AUTOSAR XML (schema 4-2-2)
package /STELLANTIS/EPT/ASWCs
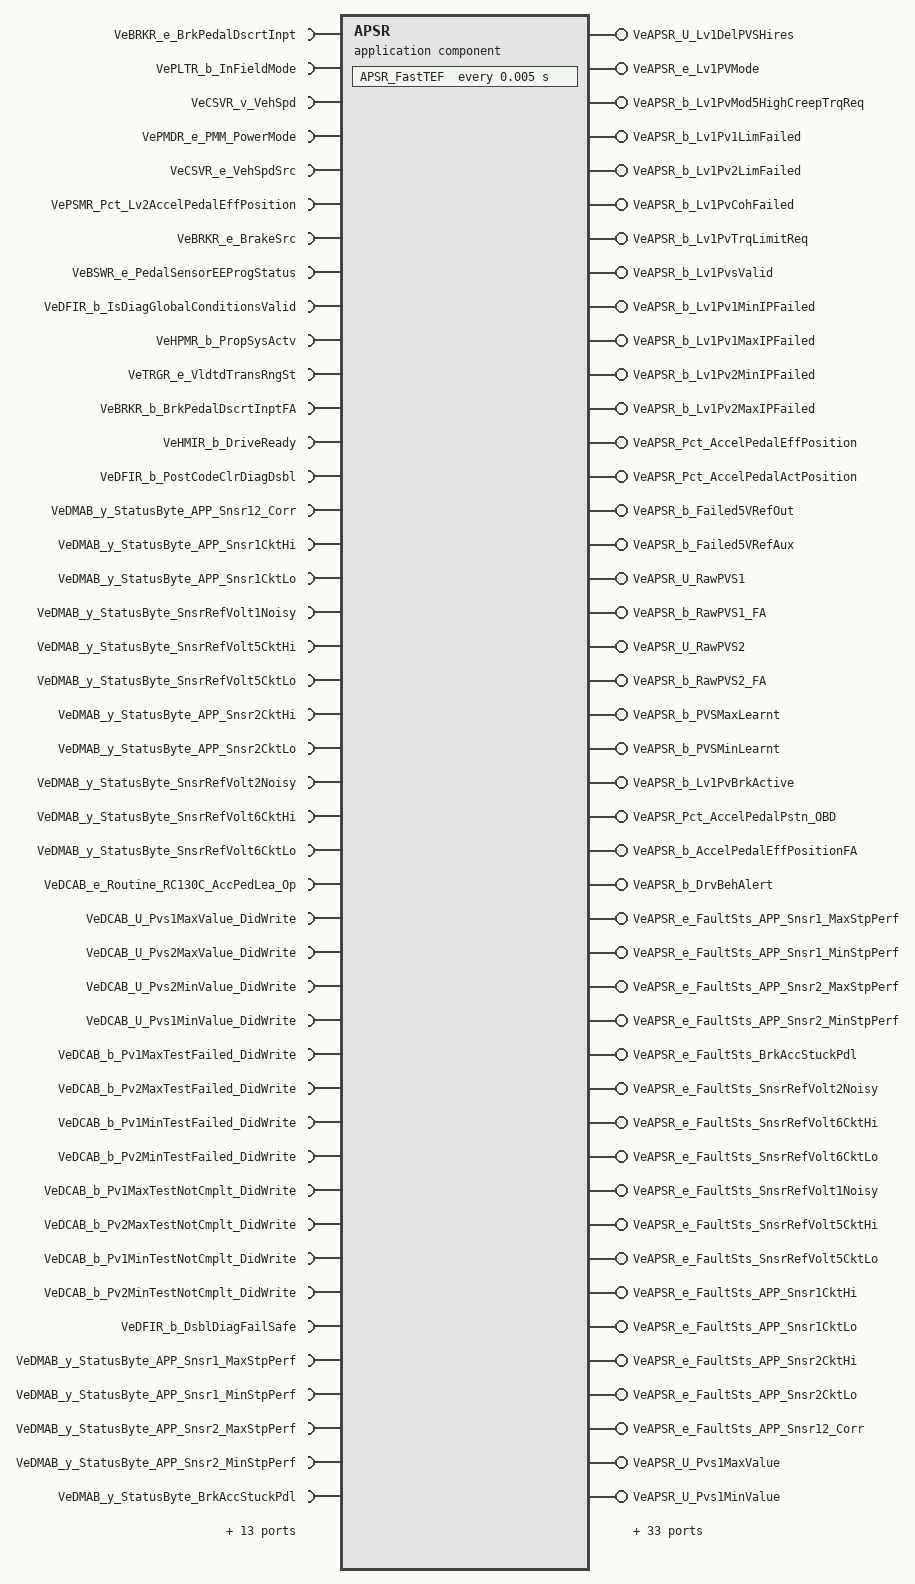
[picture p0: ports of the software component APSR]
  application sw component type APSR
    44 x require port:
      VeBRKR_e_BrkPedalDscrtInpt: variation-point={short-label=vpVeBRKR_e_BrkPedalDscrtInpt, sw-syscond=1}, nonqueued-receiver-com-spec{data-element=Value, init-value=CeBRKR_e_BrkNotApplied}, required-interface=VeBRKR_e_BrkPedalDscrtInpt
      VePLTR_b_InFieldMode: variation-point={short-label=vpVePLTR_b_InFieldMode, sw-syscond=1}, nonqueued-receiver-com-spec{data-element=Value, init-value=0}, required-interface=VePLTR_b_InFieldMode
      VeCSVR_v_VehSpd: variation-point={short-label=vpVeCSVR_v_VehSpd, sw-syscond=1}, nonqueued-receiver-com-spec{data-element=Value, init-value=0}, required-interface=VeCSVR_v_VehSpd
      VePMDR_e_PMM_PowerMode: variation-point={short-label=vpVePMDR_e_PMM_PowerMode, sw-syscond=1}, nonqueued-receiver-com-spec{data-element=Value, init-value=CePMDR_e_PowerMode_Off}, required-interface=VePMDR_e_PMM_PowerMode
      VeCSVR_e_VehSpdSrc: variation-point={short-label=vpVeCSVR_e_VehSpdSrc, sw-syscond=1}, nonqueued-receiver-com-spec{data-element=Value, init-value=CeCSVR_e_VehSpdFrmCAN}, required-interface=VeCSVR_e_VehSpdSrc
      VePSMR_Pct_Lv2AccelPedalEffPosition: variation-point={short-label=vpVePSMR_Pct_Lv2AccelPedalEffPosition, sw-syscond=1}, nonqueued-receiver-com-spec{data-element=Value, init-value=0}, required-interface=VePSMR_Pct_Lv2AccelPedalEffPosition
      VeBRKR_e_BrakeSrc: variation-point={short-label=vpVeBRKR_e_BrakeSrc, sw-syscond=1}, nonqueued-receiver-com-spec{data-element=Value, init-value=CeBRKR_e_BrkPdlDscrtInpt}, required-interface=VeBRKR_e_BrakeSrc
      VeBSWR_e_PedalSensorEEProgStatus: variation-point={short-label=vpVeBSWR_e_PedalSensorEEProgStatus, sw-syscond=1}, nonqueued-receiver-com-spec{data-element=Value, init-value=0}, required-interface=VeBSWR_e_PedalSensorEEProgStatus
      VeDFIR_b_IsDiagGlobalConditionsValid: variation-point={short-label=vpVeDFIR_b_IsDiagGlobalConditionsValid, sw-syscond=1}, nonqueued-receiver-com-spec{data-element=Value, init-value=0}, required-interface=VeDFIR_b_IsDiagGlobalConditionsValid
      VeHPMR_b_PropSysActv: variation-point={short-label=vpVeHPMR_b_PropSysActv, sw-syscond=1}, nonqueued-receiver-com-spec{data-element=Value, init-value=0}, required-interface=VeHPMR_b_PropSysActv
      VeTRGR_e_VldtdTransRngSt: variation-point={short-label=vpVeTRGR_e_VldtdTransRngSt, sw-syscond=1}, nonqueued-receiver-com-spec{data-element=Value, init-value=CeTRGR_e_NoSelectionAvailable}, required-interface=VeTRGR_e_VldtdTransRngSt
      VeBRKR_b_BrkPedalDscrtInptFA: variation-point={short-label=vpVeBRKR_b_BrkPedalDscrtInptFA, sw-syscond=1}, nonqueued-receiver-com-spec{data-element=Value, init-value=0}, required-interface=VeBRKR_b_BrkPedalDscrtInptFA
      VeHMIR_b_DriveReady: variation-point={short-label=vpVeHMIR_b_DriveReady, sw-syscond=1}, nonqueued-receiver-com-spec{data-element=Value, init-value=0}, required-interface=VeHMIR_b_DriveReady
      VeDFIR_b_PostCodeClrDiagDsbl: variation-point={short-label=vpVeDFIR_b_PostCodeClrDiagDsbl, sw-syscond=1}, nonqueued-receiver-com-spec{data-element=Value, init-value=0}, required-interface=VeDFIR_b_PostCodeClrDiagDsbl
      VeDMAB_y_StatusByte_APP_Snsr12_Corr: variation-point={short-label=vpVeDMAB_y_StatusByte_APP_Snsr12_Corr, sw-syscond=1}, nonqueued-receiver-com-spec{data-element=Value, init-value=0}, required-interface=VeDMAB_y_StatusByte_APP_Snsr12_Corr
      VeDMAB_y_StatusByte_APP_Snsr1CktHi: variation-point={short-label=vpVeDMAB_y_StatusByte_APP_Snsr1CktHi, sw-syscond=1}, nonqueued-receiver-com-spec{data-element=Value, init-value=0}, required-interface=VeDMAB_y_StatusByte_APP_Snsr1CktHi
      VeDMAB_y_StatusByte_APP_Snsr1CktLo: variation-point={short-label=vpVeDMAB_y_StatusByte_APP_Snsr1CktLo, sw-syscond=1}, nonqueued-receiver-com-spec{data-element=Value, init-value=0}, required-interface=VeDMAB_y_StatusByte_APP_Snsr1CktLo
      VeDMAB_y_StatusByte_SnsrRefVolt1Noisy: variation-point={short-label=vpVeDMAB_y_StatusByte_SnsrRefVolt1Noisy, sw-syscond=1}, nonqueued-receiver-com-spec{data-element=Value, init-value=0}, required-interface=VeDMAB_y_StatusByte_SnsrRefVolt1Noisy
      VeDMAB_y_StatusByte_SnsrRefVolt5CktHi: variation-point={short-label=vpVeDMAB_y_StatusByte_SnsrRefVolt5CktHi, sw-syscond=1}, nonqueued-receiver-com-spec{data-element=Value, init-value=0}, required-interface=VeDMAB_y_StatusByte_SnsrRefVolt5CktHi
      VeDMAB_y_StatusByte_SnsrRefVolt5CktLo: variation-point={short-label=vpVeDMAB_y_StatusByte_SnsrRefVolt5CktLo, sw-syscond=1}, nonqueued-receiver-com-spec{data-element=Value, init-value=0}, required-interface=VeDMAB_y_StatusByte_SnsrRefVolt5CktLo
      VeDMAB_y_StatusByte_APP_Snsr2CktHi: variation-point={short-label=vpVeDMAB_y_StatusByte_APP_Snsr2CktHi, sw-syscond=1}, nonqueued-receiver-com-spec{data-element=Value, init-value=0}, required-interface=VeDMAB_y_StatusByte_APP_Snsr2CktHi
      VeDMAB_y_StatusByte_APP_Snsr2CktLo: variation-point={short-label=vpVeDMAB_y_StatusByte_APP_Snsr2CktLo, sw-syscond=1}, nonqueued-receiver-com-spec{data-element=Value, init-value=0}, required-interface=VeDMAB_y_StatusByte_APP_Snsr2CktLo
      VeDMAB_y_StatusByte_SnsrRefVolt2Noisy: variation-point={short-label=vpVeDMAB_y_StatusByte_SnsrRefVolt2Noisy, sw-syscond=1}, nonqueued-receiver-com-spec{data-element=Value, init-value=0}, required-interface=VeDMAB_y_StatusByte_SnsrRefVolt2Noisy
      VeDMAB_y_StatusByte_SnsrRefVolt6CktHi: variation-point={short-label=vpVeDMAB_y_StatusByte_SnsrRefVolt6CktHi, sw-syscond=1}, nonqueued-receiver-com-spec{data-element=Value, init-value=0}, required-interface=VeDMAB_y_StatusByte_SnsrRefVolt6CktHi
      VeDMAB_y_StatusByte_SnsrRefVolt6CktLo: variation-point={short-label=vpVeDMAB_y_StatusByte_SnsrRefVolt6CktLo, sw-syscond=1}, nonqueued-receiver-com-spec{data-element=Value, init-value=0}, required-interface=VeDMAB_y_StatusByte_SnsrRefVolt6CktLo
      VeDCAB_e_Routine_RC130C_AccPedLea_Op: variation-point={short-label=vpVeDCAB_e_Routine_RC130C_AccPedLea_Op, sw-syscond=1}, nonqueued-receiver-com-spec{data-element=Value, init-value=CeDCAB_e_Routine_NOP}, required-interface=VeDCAB_e_Routine_RC130C_AccPedLea_Op
      VeDCAB_U_Pvs1MaxValue_DidWrite: nonqueued-receiver-com-spec{data-element=Value, init-value=0}, required-interface=VeDCAB_U_Pvs1MaxValue_DidWrite
      VeDCAB_U_Pvs2MaxValue_DidWrite: nonqueued-receiver-com-spec{data-element=Value, init-value=0}, required-interface=VeDCAB_U_Pvs2MaxValue_DidWrite
      VeDCAB_U_Pvs2MinValue_DidWrite: nonqueued-receiver-com-spec{data-element=Value, init-value=0}, required-interface=VeDCAB_U_Pvs2MinValue_DidWrite
      VeDCAB_U_Pvs1MinValue_DidWrite: nonqueued-receiver-com-spec{data-element=Value, init-value=0}, required-interface=VeDCAB_U_Pvs1MinValue_DidWrite
      VeDCAB_b_Pv1MaxTestFailed_DidWrite: nonqueued-receiver-com-spec{data-element=Value, init-value=0}, required-interface=VeDCAB_b_Pv1MaxTestFailed_DidWrite
      VeDCAB_b_Pv2MaxTestFailed_DidWrite: nonqueued-receiver-com-spec{data-element=Value, init-value=0}, required-interface=VeDCAB_b_Pv2MaxTestFailed_DidWrite
      VeDCAB_b_Pv1MinTestFailed_DidWrite: nonqueued-receiver-com-spec{data-element=Value, init-value=0}, required-interface=VeDCAB_b_Pv1MinTestFailed_DidWrite
      VeDCAB_b_Pv2MinTestFailed_DidWrite: nonqueued-receiver-com-spec{data-element=Value, init-value=0}, required-interface=VeDCAB_b_Pv2MinTestFailed_DidWrite
      VeDCAB_b_Pv1MaxTestNotCmplt_DidWrite: nonqueued-receiver-com-spec{data-element=Value, init-value=0}, required-interface=VeDCAB_b_Pv1MaxTestNotCmplt_DidWrite
      VeDCAB_b_Pv2MaxTestNotCmplt_DidWrite: nonqueued-receiver-com-spec{data-element=Value, init-value=0}, required-interface=VeDCAB_b_Pv2MaxTestNotCmplt_DidWrite
      VeDCAB_b_Pv1MinTestNotCmplt_DidWrite: nonqueued-receiver-com-spec{data-element=Value, init-value=0}, required-interface=VeDCAB_b_Pv1MinTestNotCmplt_DidWrite
      VeDCAB_b_Pv2MinTestNotCmplt_DidWrite: nonqueued-receiver-com-spec{data-element=Value, init-value=0}, required-interface=VeDCAB_b_Pv2MinTestNotCmplt_DidWrite
      VeDFIR_b_DsblDiagFailSafe: variation-point={short-label=vpVeDFIR_b_DsblDiagFailSafe, sw-syscond=1}, nonqueued-receiver-com-spec{data-element=Value, init-value=0}, required-interface=VeDFIR_b_DsblDiagFailSafe
      VeDMAB_y_StatusByte_APP_Snsr1_MaxStpPerf: variation-point={short-label=vpVeDMAB_y_StatusByte_APP_Snsr1_MaxStpPerf, sw-syscond=1}, nonqueued-receiver-com-spec{data-element=Value, init-value=0}, required-interface=VeDMAB_y_StatusByte_APP_Snsr1_MaxStpPerf
      VeDMAB_y_StatusByte_APP_Snsr1_MinStpPerf: variation-point={short-label=vpVeDMAB_y_StatusByte_APP_Snsr1_MinStpPerf, sw-syscond=1}, nonqueued-receiver-com-spec{data-element=Value, init-value=0}, required-interface=VeDMAB_y_StatusByte_APP_Snsr1_MinStpPerf
      VeDMAB_y_StatusByte_APP_Snsr2_MaxStpPerf: variation-point={short-label=vpVeDMAB_y_StatusByte_APP_Snsr2_MaxStpPerf, sw-syscond=1}, nonqueued-receiver-com-spec{data-element=Value, init-value=0}, required-interface=VeDMAB_y_StatusByte_APP_Snsr2_MaxStpPerf
      VeDMAB_y_StatusByte_APP_Snsr2_MinStpPerf: variation-point={short-label=vpVeDMAB_y_StatusByte_APP_Snsr2_MinStpPerf, sw-syscond=1}, nonqueued-receiver-com-spec{data-element=Value, init-value=0}, required-interface=VeDMAB_y_StatusByte_APP_Snsr2_MinStpPerf
      VeDMAB_y_StatusByte_BrkAccStuckPdl: variation-point={short-label=vpVeDMAB_y_StatusByte_BrkAccStuckPdl, sw-syscond=1}, nonqueued-receiver-com-spec{data-element=Value, init-value=0}, required-interface=VeDMAB_y_StatusByte_BrkAccStuckPdl
    64 x provide port:
      VeAPSR_U_Lv1DelPVSHires: nonqueued-sender-com-spec{data-element=Value, init-value=0}, provided-interface=VeAPSR_U_Lv1DelPVSHires
      VeAPSR_e_Lv1PVMode: nonqueued-sender-com-spec{data-element=Value, init-value=CeAPSR_e_LV1PVMode_NotValid}, provided-interface=VeAPSR_e_Lv1PVMode
      VeAPSR_b_Lv1PvMod5HighCreepTrqReq: nonqueued-sender-com-spec{data-element=Value, init-value=0}, provided-interface=VeAPSR_b_Lv1PvMod5HighCreepTrqReq
      VeAPSR_b_Lv1Pv1LimFailed: nonqueued-sender-com-spec{data-element=Value, init-value=0}, provided-interface=VeAPSR_b_Lv1Pv1LimFailed
      VeAPSR_b_Lv1Pv2LimFailed: nonqueued-sender-com-spec{data-element=Value, init-value=0}, provided-interface=VeAPSR_b_Lv1Pv2LimFailed
      VeAPSR_b_Lv1PvCohFailed: nonqueued-sender-com-spec{data-element=Value, init-value=0}, provided-interface=VeAPSR_b_Lv1PvCohFailed
      VeAPSR_b_Lv1PvTrqLimitReq: nonqueued-sender-com-spec{data-element=Value, init-value=0}, provided-interface=VeAPSR_b_Lv1PvTrqLimitReq
      VeAPSR_b_Lv1PvsValid: nonqueued-sender-com-spec{data-element=Value, init-value=0}, provided-interface=VeAPSR_b_Lv1PvsValid
      VeAPSR_b_Lv1Pv1MinIPFailed: nonqueued-sender-com-spec{data-element=Value, init-value=0}, provided-interface=VeAPSR_b_Lv1Pv1MinIPFailed
      VeAPSR_b_Lv1Pv1MaxIPFailed: nonqueued-sender-com-spec{data-element=Value, init-value=0}, provided-interface=VeAPSR_b_Lv1Pv1MaxIPFailed
      VeAPSR_b_Lv1Pv2MinIPFailed: nonqueued-sender-com-spec{data-element=Value, init-value=0}, provided-interface=VeAPSR_b_Lv1Pv2MinIPFailed
      VeAPSR_b_Lv1Pv2MaxIPFailed: nonqueued-sender-com-spec{data-element=Value, init-value=0}, provided-interface=VeAPSR_b_Lv1Pv2MaxIPFailed
      VeAPSR_Pct_AccelPedalEffPosition: variation-point={short-label=vpVeAPSR_Pct_AccelPedalEffPosition, sw-syscond=1}, nonqueued-sender-com-spec{data-element=Value, init-value=0}, provided-interface=VeAPSR_Pct_AccelPedalEffPosition
      VeAPSR_Pct_AccelPedalActPosition: variation-point={short-label=vpVeAPSR_Pct_AccelPedalActPosition, sw-syscond=1}, nonqueued-sender-com-spec{data-element=Value, init-value=0}, provided-interface=VeAPSR_Pct_AccelPedalActPosition
      VeAPSR_b_Failed5VRefOut: nonqueued-sender-com-spec{data-element=Value, init-value=0}, provided-interface=VeAPSR_b_Failed5VRefOut
      VeAPSR_b_Failed5VRefAux: nonqueued-sender-com-spec{data-element=Value, init-value=0}, provided-interface=VeAPSR_b_Failed5VRefAux
      VeAPSR_U_RawPVS1: variation-point={short-label=vpVeAPSR_U_RawPVS1, sw-syscond=1}, nonqueued-sender-com-spec{data-element=Value, init-value=0}, provided-interface=VeAPSR_U_RawPVS1
      VeAPSR_b_RawPVS1_FA: variation-point={short-label=vpVeAPSR_b_RawPVS1_FA, sw-syscond=1}, nonqueued-sender-com-spec{data-element=Value, init-value=0}, provided-interface=VeAPSR_b_RawPVS1_FA
      VeAPSR_U_RawPVS2: variation-point={short-label=vpVeAPSR_U_RawPVS2, sw-syscond=1}, nonqueued-sender-com-spec{data-element=Value, init-value=0}, provided-interface=VeAPSR_U_RawPVS2
      VeAPSR_b_RawPVS2_FA: variation-point={short-label=vpVeAPSR_b_RawPVS2_FA, sw-syscond=1}, nonqueued-sender-com-spec{data-element=Value, init-value=0}, provided-interface=VeAPSR_b_RawPVS2_FA
      VeAPSR_b_PVSMaxLearnt: nonqueued-sender-com-spec{data-element=Value, init-value=0}, provided-interface=VeAPSR_b_PVSMaxLearnt
      VeAPSR_b_PVSMinLearnt: nonqueued-sender-com-spec{data-element=Value, init-value=0}, provided-interface=VeAPSR_b_PVSMinLearnt
      VeAPSR_b_Lv1PvBrkActive: nonqueued-sender-com-spec{data-element=Value, init-value=0}, provided-interface=VeAPSR_b_Lv1PvBrkActive
      VeAPSR_Pct_AccelPedalPstn_OBD: nonqueued-sender-com-spec{data-element=Value, init-value=0}, provided-interface=VeAPSR_Pct_AccelPedalPstn_OBD
      VeAPSR_b_AccelPedalEffPositionFA: nonqueued-sender-com-spec{data-element=Value, init-value=0}, provided-interface=VeAPSR_b_AccelPedalEffPositionFA
      VeAPSR_b_DrvBehAlert: nonqueued-sender-com-spec{data-element=Value, init-value=0}, provided-interface=VeAPSR_b_DrvBehAlert
      VeAPSR_e_FaultSts_APP_Snsr1_MaxStpPerf: nonqueued-sender-com-spec{data-element=Value, init-value=CeDFIB_e_Init}, provided-interface=VeAPSR_e_FaultSts_APP_Snsr1_MaxStpPerf
      VeAPSR_e_FaultSts_APP_Snsr1_MinStpPerf: nonqueued-sender-com-spec{data-element=Value, init-value=CeDFIB_e_Init}, provided-interface=VeAPSR_e_FaultSts_APP_Snsr1_MinStpPerf
      VeAPSR_e_FaultSts_APP_Snsr2_MaxStpPerf: nonqueued-sender-com-spec{data-element=Value, init-value=CeDFIB_e_Init}, provided-interface=VeAPSR_e_FaultSts_APP_Snsr2_MaxStpPerf
      VeAPSR_e_FaultSts_APP_Snsr2_MinStpPerf: nonqueued-sender-com-spec{data-element=Value, init-value=CeDFIB_e_Init}, provided-interface=VeAPSR_e_FaultSts_APP_Snsr2_MinStpPerf
      VeAPSR_e_FaultSts_BrkAccStuckPdl: nonqueued-sender-com-spec{data-element=Value, init-value=CeDFIB_e_Init}, provided-interface=VeAPSR_e_FaultSts_BrkAccStuckPdl
      VeAPSR_e_FaultSts_SnsrRefVolt2Noisy: nonqueued-sender-com-spec{data-element=Value, init-value=CeDFIB_e_Init}, provided-interface=VeAPSR_e_FaultSts_SnsrRefVolt2Noisy
      VeAPSR_e_FaultSts_SnsrRefVolt6CktHi: nonqueued-sender-com-spec{data-element=Value, init-value=CeDFIB_e_Init}, provided-interface=VeAPSR_e_FaultSts_SnsrRefVolt6CktHi
      VeAPSR_e_FaultSts_SnsrRefVolt6CktLo: nonqueued-sender-com-spec{data-element=Value, init-value=CeDFIB_e_Init}, provided-interface=VeAPSR_e_FaultSts_SnsrRefVolt6CktLo
      VeAPSR_e_FaultSts_SnsrRefVolt1Noisy: nonqueued-sender-com-spec{data-element=Value, init-value=CeDFIB_e_Init}, provided-interface=VeAPSR_e_FaultSts_SnsrRefVolt1Noisy
      VeAPSR_e_FaultSts_SnsrRefVolt5CktHi: nonqueued-sender-com-spec{data-element=Value, init-value=CeDFIB_e_Init}, provided-interface=VeAPSR_e_FaultSts_SnsrRefVolt5CktHi
      VeAPSR_e_FaultSts_SnsrRefVolt5CktLo: nonqueued-sender-com-spec{data-element=Value, init-value=CeDFIB_e_Init}, provided-interface=VeAPSR_e_FaultSts_SnsrRefVolt5CktLo
      VeAPSR_e_FaultSts_APP_Snsr1CktHi: nonqueued-sender-com-spec{data-element=Value, init-value=CeDFIB_e_Init}, provided-interface=VeAPSR_e_FaultSts_APP_Snsr1CktHi
      VeAPSR_e_FaultSts_APP_Snsr1CktLo: nonqueued-sender-com-spec{data-element=Value, init-value=CeDFIB_e_Init}, provided-interface=VeAPSR_e_FaultSts_APP_Snsr1CktLo
      VeAPSR_e_FaultSts_APP_Snsr2CktHi: nonqueued-sender-com-spec{data-element=Value, init-value=CeDFIB_e_Init}, provided-interface=VeAPSR_e_FaultSts_APP_Snsr2CktHi
      VeAPSR_e_FaultSts_APP_Snsr2CktLo: nonqueued-sender-com-spec{data-element=Value, init-value=CeDFIB_e_Init}, provided-interface=VeAPSR_e_FaultSts_APP_Snsr2CktLo
      VeAPSR_e_FaultSts_APP_Snsr12_Corr: nonqueued-sender-com-spec{data-element=Value, init-value=CeDFIB_e_Init}, provided-interface=VeAPSR_e_FaultSts_APP_Snsr12_Corr
      VeAPSR_U_Pvs1MaxValue: nonqueued-sender-com-spec{data-element=Value, init-value=0}, provided-interface=VeAPSR_U_Pvs1MaxValue
      VeAPSR_U_Pvs1MinValue: nonqueued-sender-com-spec{data-element=Value, init-value=0}, provided-interface=VeAPSR_U_Pvs1MinValue
      VeAPSR_U_Pvs2MaxValue: nonqueued-sender-com-spec{data-element=Value, init-value=0}, provided-interface=VeAPSR_U_Pvs2MaxValue
      VeAPSR_U_Pvs2MinValue: nonqueued-sender-com-spec{data-element=Value, init-value=0}, provided-interface=VeAPSR_U_Pvs2MinValue
      VeAPSR_b_Pv1MaxTestFailed: nonqueued-sender-com-spec{data-element=Value, init-value=0}, provided-interface=VeAPSR_b_Pv1MaxTestFailed
      VeAPSR_b_Pv1MaxTestNotCmplt: nonqueued-sender-com-spec{data-element=Value, init-value=0}, provided-interface=VeAPSR_b_Pv1MaxTestNotCmplt
      VeAPSR_b_Pv1MinTestFailed: nonqueued-sender-com-spec{data-element=Value, init-value=0}, provided-interface=VeAPSR_b_Pv1MinTestFailed
      VeAPSR_b_Pv1MinTestNotCmplt: nonqueued-sender-com-spec{data-element=Value, init-value=0}, provided-interface=VeAPSR_b_Pv1MinTestNotCmplt
      VeAPSR_b_Pv2MaxTestFailed: nonqueued-sender-com-spec{data-element=Value, init-value=0}, provided-interface=VeAPSR_b_Pv2MaxTestFailed
      VeAPSR_b_Pv2MaxTestNotCmplt: nonqueued-sender-com-spec{data-element=Value, init-value=0}, provided-interface=VeAPSR_b_Pv2MaxTestNotCmplt
      VeAPSR_b_Pv2MinTestFailed: nonqueued-sender-com-spec{data-element=Value, init-value=0}, provided-interface=VeAPSR_b_Pv2MinTestFailed
      VeAPSR_b_Pv2MinTestNotCmplt: nonqueued-sender-com-spec{data-element=Value, init-value=0}, provided-interface=VeAPSR_b_Pv2MinTestNotCmplt
      VeAPSR_b_KickDown: nonqueued-sender-com-spec{data-element=Value, init-value=0}, provided-interface=VeAPSR_b_KickDown
      FsftAPSR_Pct_AccelPedalActPosition: server-com-spec=FsftAPSR_Pct_AccelPedalActPosition, provided-interface=FsftAPSR_Pct_AccelPedalActPosition
      FsftAPSR_Pct_AccelPedalEffPosition: server-com-spec=FsftAPSR_Pct_AccelPedalEffPosition, provided-interface=FsftAPSR_Pct_AccelPedalEffPosition
      PokeAPSR_Pct_AccelPedalActPosition: server-com-spec{operation=PokeAPSR_Pct_AccelPedalActPosition, queue-length=1}, provided-interface=PokeAPSR_Pct_AccelPedalActPosition
      PokeAPSR_Pct_AccelPedalEffPosition: server-com-spec{operation=PokeAPSR_Pct_AccelPedalEffPosition, queue-length=1}, provided-interface=PokeAPSR_Pct_AccelPedalEffPosition
      PokeAPSR_Pct_AccelPedalPstn_OBD: server-com-spec{operation=PokeAPSR_Pct_AccelPedalPstn_OBD, queue-length=1}, provided-interface=PokeAPSR_Pct_AccelPedalPstn_OBD
      PokeAPSR_U_RawAux5V: server-com-spec{operation=PokeAPSR_U_RawAux5V, queue-length=1}, provided-interface=PokeAPSR_U_RawAux5V
      PokeAPSR_U_RawOut5V: server-com-spec{operation=PokeAPSR_U_RawOut5V, queue-length=1}, provided-interface=PokeAPSR_U_RawOut5V
      PokeAPSR_U_RawPVS1: server-com-spec{operation=PokeAPSR_U_RawPVS1, queue-length=1}, provided-interface=PokeAPSR_U_RawPVS1
      PokeAPSR_U_RawPVS2: server-com-spec{operation=PokeAPSR_U_RawPVS2, queue-length=1}, provided-interface=PokeAPSR_U_RawPVS2
    13 x require port:
      NeAPSR_U_Lv1PvAdapt_Rx: nv-require-com-spec{init-value=0, variable=NeAPSR_U_Lv1PvAdapt}, required-interface=NeAPSR_U_Lv1PvAdapt
      AeAPSR_b_Pv1MaxTestFailed_Rx: nv-require-com-spec{init-value=0, variable=AeAPSR_b_Pv1MaxTestFailed}, required-interface=AeAPSR_b_Pv1MaxTestFailed
      AeAPSR_b_Pv1MaxTestNotCmplt_Rx: nv-require-com-spec{init-value=0, variable=AeAPSR_b_Pv1MaxTestNotCmplt}, required-interface=AeAPSR_b_Pv1MaxTestNotCmplt
      AeAPSR_b_Pv1MinTestFailed_Rx: nv-require-com-spec{init-value=0, variable=AeAPSR_b_Pv1MinTestFailed}, required-interface=AeAPSR_b_Pv1MinTestFailed
      AeAPSR_b_Pv1MinTestNotCmplt_Rx: nv-require-com-spec{init-value=0, variable=AeAPSR_b_Pv1MinTestNotCmplt}, required-interface=AeAPSR_b_Pv1MinTestNotCmplt
      AeAPSR_b_Pv2MaxTestFailed_Rx: nv-require-com-spec{init-value=0, variable=AeAPSR_b_Pv2MaxTestFailed}, required-interface=AeAPSR_b_Pv2MaxTestFailed
      AeAPSR_b_Pv2MaxTestNotCmplt_Rx: nv-require-com-spec{init-value=0, variable=AeAPSR_b_Pv2MaxTestNotCmplt}, required-interface=AeAPSR_b_Pv2MaxTestNotCmplt
      AeAPSR_b_Pv2MinTestFailed_Rx: nv-require-com-spec{init-value=0, variable=AeAPSR_b_Pv2MinTestFailed}, required-interface=AeAPSR_b_Pv2MinTestFailed
      AeAPSR_b_Pv2MinTestNotCmplt_Rx: nv-require-com-spec{init-value=0, variable=AeAPSR_b_Pv2MinTestNotCmplt}, required-interface=AeAPSR_b_Pv2MinTestNotCmplt
      AeAPSR_U_Pvs1MaxValue_Rx: nv-require-com-spec{init-value=0, variable=AeAPSR_U_Pvs1MaxValue}, required-interface=AeAPSR_U_Pvs1MaxValue
      AeAPSR_U_Pvs1MinValue_Rx: nv-require-com-spec{init-value=0, variable=AeAPSR_U_Pvs1MinValue}, required-interface=AeAPSR_U_Pvs1MinValue
      AeAPSR_U_Pvs2MaxValue_Rx: nv-require-com-spec{init-value=0, variable=AeAPSR_U_Pvs2MaxValue}, required-interface=AeAPSR_U_Pvs2MaxValue
      AeAPSR_U_Pvs2MinValue_Rx: nv-require-com-spec{init-value=0, variable=AeAPSR_U_Pvs2MinValue}, required-interface=AeAPSR_U_Pvs2MinValue
    13 x provide port:
      NeAPSR_U_Lv1PvAdapt: nv-provide-com-spec{ram-block-init-value=0, variable=NeAPSR_U_Lv1PvAdapt}, provided-interface=NeAPSR_U_Lv1PvAdapt
      AeAPSR_b_Pv1MaxTestFailed: variation-point={short-label=vpAeAPSR_b_Pv1MaxTestFailed, sw-syscond=1}, nv-provide-com-spec{ram-block-init-value=0, variable=AeAPSR_b_Pv1MaxTestFailed}, provided-interface=AeAPSR_b_Pv1MaxTestFailed
      AeAPSR_b_Pv1MaxTestNotCmplt: variation-point={short-label=vpAeAPSR_b_Pv1MaxTestNotCmplt, sw-syscond=1}, nv-provide-com-spec{ram-block-init-value=0, variable=AeAPSR_b_Pv1MaxTestNotCmplt}, provided-interface=AeAPSR_b_Pv1MaxTestNotCmplt
      AeAPSR_b_Pv1MinTestFailed: variation-point={short-label=vpAeAPSR_b_Pv1MinTestFailed, sw-syscond=1}, nv-provide-com-spec{ram-block-init-value=0, variable=AeAPSR_b_Pv1MinTestFailed}, provided-interface=AeAPSR_b_Pv1MinTestFailed
      AeAPSR_b_Pv1MinTestNotCmplt: variation-point={short-label=vpAeAPSR_b_Pv1MinTestNotCmplt, sw-syscond=1}, nv-provide-com-spec{ram-block-init-value=0, variable=AeAPSR_b_Pv1MinTestNotCmplt}, provided-interface=AeAPSR_b_Pv1MinTestNotCmplt
      AeAPSR_b_Pv2MaxTestFailed: variation-point={short-label=vpAeAPSR_b_Pv2MaxTestFailed, sw-syscond=1}, nv-provide-com-spec{ram-block-init-value=0, variable=AeAPSR_b_Pv2MaxTestFailed}, provided-interface=AeAPSR_b_Pv2MaxTestFailed
      AeAPSR_b_Pv2MaxTestNotCmplt: variation-point={short-label=vpAeAPSR_b_Pv2MaxTestNotCmplt, sw-syscond=1}, nv-provide-com-spec{ram-block-init-value=0, variable=AeAPSR_b_Pv2MaxTestNotCmplt}, provided-interface=AeAPSR_b_Pv2MaxTestNotCmplt
      AeAPSR_b_Pv2MinTestFailed: variation-point={short-label=vpAeAPSR_b_Pv2MinTestFailed, sw-syscond=1}, nv-provide-com-spec{ram-block-init-value=0, variable=AeAPSR_b_Pv2MinTestFailed}, provided-interface=AeAPSR_b_Pv2MinTestFailed
      AeAPSR_b_Pv2MinTestNotCmplt: variation-point={short-label=vpAeAPSR_b_Pv2MinTestNotCmplt, sw-syscond=1}, nv-provide-com-spec{ram-block-init-value=0, variable=AeAPSR_b_Pv2MinTestNotCmplt}, provided-interface=AeAPSR_b_Pv2MinTestNotCmplt
      AeAPSR_U_Pvs1MaxValue: variation-point={short-label=vpAeAPSR_U_Pvs1MaxValue, sw-syscond=1}, nv-provide-com-spec{ram-block-init-value=0, variable=AeAPSR_U_Pvs1MaxValue}, provided-interface=AeAPSR_U_Pvs1MaxValue
      AeAPSR_U_Pvs1MinValue: variation-point={short-label=vpAeAPSR_U_Pvs1MinValue, sw-syscond=1}, nv-provide-com-spec{ram-block-init-value=0, variable=AeAPSR_U_Pvs1MinValue}, provided-interface=AeAPSR_U_Pvs1MinValue
      AeAPSR_U_Pvs2MaxValue: variation-point={short-label=vpAeAPSR_U_Pvs2MaxValue, sw-syscond=1}, nv-provide-com-spec{ram-block-init-value=0, variable=AeAPSR_U_Pvs2MaxValue}, provided-interface=AeAPSR_U_Pvs2MaxValue
      AeAPSR_U_Pvs2MinValue: variation-point={short-label=vpAeAPSR_U_Pvs2MinValue, sw-syscond=1}, nv-provide-com-spec{ram-block-init-value=0, variable=AeAPSR_U_Pvs2MinValue}, provided-interface=AeAPSR_U_Pvs2MinValue
    behavior IB_APSR: data-type-mapping=msADTtoIDTMapping, handle-termination-and-restart=NO-SUPPORT
      timing event Event_FastTEF: start-on-event=APSR_FastTEF, period=0.005
      4 x operation invoked event:
        Event_PokeAPSR_U_RawAux5V: start-on-event=PokeAPSR_U_RawAux5V, operation=PokeAPSR_U_RawAux5V.PokeAPSR_U_RawAux5V
        Event_PokeAPSR_U_RawOut5V: start-on-event=PokeAPSR_U_RawOut5V, operation=PokeAPSR_U_RawOut5V.PokeAPSR_U_RawOut5V
        Event_PokeAPSR_U_RawPVS1: start-on-event=PokeAPSR_U_RawPVS1, operation=PokeAPSR_U_RawPVS1.PokeAPSR_U_RawPVS1
        Event_PokeAPSR_U_RawPVS2: start-on-event=PokeAPSR_U_RawPVS2, operation=PokeAPSR_U_RawPVS2.PokeAPSR_U_RawPVS2
      init event Event_APSR_ac_Init: start-on-event=APSR_ac_Init
      init event Event_PwrOn: start-on-event=APSR_PwrOn
      init event Event_PwrOff: start-on-event=APSR_PwrOff
      6 x data received event:
        Event_Routine_RC130C_AccPedLea: start-on-event=Routine_RC130C_AccPedLea, data=VeDCAB_e_Routine_RC130C_AccPedLea_Op.Value
        Event_DIDWrite_RWD9E21_IPEEETCPVS1MAXVAL: start-on-event=DIDWrite_RWD9E21_IPEEETCPVS1MAXVAL, data=VeDCAB_U_Pvs1MaxValue_DidWrite.Value
        Event_DIDWrite_RWD9E23_IPEEETCPVS2MAXVAL: start-on-event=DIDWrite_RWD9E23_IPEEETCPVS2MAXVAL, data=VeDCAB_U_Pvs2MaxValue_DidWrite.Value
        Event_DIDWrite_RWD9E22_IPEEETCPVS2MINVAL: start-on-event=DIDWrite_RWD9E22_IPEEETCPVS2MINVAL, data=VeDCAB_U_Pvs2MinValue_DidWrite.Value
        Event_DIDWrite_RWD9E20_IPEEETCPVS1MINVAL: start-on-event=DIDWrite_RWD9E20_IPEEETCPVS1MINVAL, data=VeDCAB_U_Pvs1MinValue_DidWrite.Value
        Event_DIDWrite_RWD9E15_IPEEREG16FLG: start-on-event=DIDWrite_RWD9E15_IPEEREG16FLG, data=VeDCAB_b_Pv1MaxTestFailed_DidWrite.Value
      explicit-inter-runnable-variables:
        8 x data, all with category=VALUE, sw-calibration-access=READ-ONLY, init-value=0:
          ServRoutStrt_write_IRV: type=Boolean, variation-point={short-label=vpServRoutStrt_write_IRV, sw-syscond=1}
          RawOut5V_FA_Init_write_IRV: type=Boolean, variation-point={short-label=vpRawOut5V_FA_Init_write_IRV, sw-syscond=1}
          RawAux5V_FA_Init_write_IRV: type=Boolean, variation-point={short-label=vpRawAux5V_FA_Init_write_IRV, sw-syscond=1}
          RawPVS1_write_IRV: type=Float, variation-point={short-label=vpRawPVS1_write_IRV, sw-syscond=1}
          RawPVS2_write_IRV: type=Float, variation-point={short-label=vpRawPVS2_write_IRV, sw-syscond=1}
          RawOut5V_Init_write_IRV: type=Float, variation-point={short-label=vpRawOut5V_Init_write_IRV, sw-syscond=1}
          RawAux5V_Init_write_IRV: type=Float, variation-point={short-label=vpRawAux5V_Init_write_IRV, sw-syscond=1}
          LeAPSR_b_AccelPedalEffPositionFA_write_IRV: type=Boolean
      14 x runnable:
        APSR_ac_Init
          data-send-points:
            17 x access:
              OUT_VeAPSR_e_Lv1PVMode_Value: accessed-variable=VeAPSR_e_Lv1PVMode.Value
              OUT_VeAPSR_e_FaultSts_APP_Snsr1_MaxStpPerf_Value: accessed-variable=VeAPSR_e_FaultSts_APP_Snsr1_MaxStpPerf.Value
              OUT_VeAPSR_e_FaultSts_APP_Snsr1_MinStpPerf_Value: accessed-variable=VeAPSR_e_FaultSts_APP_Snsr1_MinStpPerf.Value
              OUT_VeAPSR_e_FaultSts_APP_Snsr2_MaxStpPerf_Value: accessed-variable=VeAPSR_e_FaultSts_APP_Snsr2_MaxStpPerf.Value
              OUT_VeAPSR_e_FaultSts_APP_Snsr2_MinStpPerf_Value: accessed-variable=VeAPSR_e_FaultSts_APP_Snsr2_MinStpPerf.Value
              OUT_VeAPSR_e_FaultSts_BrkAccStuckPdl_Value: accessed-variable=VeAPSR_e_FaultSts_BrkAccStuckPdl.Value
              OUT_VeAPSR_e_FaultSts_SnsrRefVolt2Noisy_Value: accessed-variable=VeAPSR_e_FaultSts_SnsrRefVolt2Noisy.Value
              OUT_VeAPSR_e_FaultSts_SnsrRefVolt6CktHi_Value: accessed-variable=VeAPSR_e_FaultSts_SnsrRefVolt6CktHi.Value
              OUT_VeAPSR_e_FaultSts_SnsrRefVolt6CktLo_Value: accessed-variable=VeAPSR_e_FaultSts_SnsrRefVolt6CktLo.Value
              OUT_VeAPSR_e_FaultSts_SnsrRefVolt1Noisy_Value: accessed-variable=VeAPSR_e_FaultSts_SnsrRefVolt1Noisy.Value
              OUT_VeAPSR_e_FaultSts_SnsrRefVolt5CktHi_Value: accessed-variable=VeAPSR_e_FaultSts_SnsrRefVolt5CktHi.Value
              OUT_VeAPSR_e_FaultSts_SnsrRefVolt5CktLo_Value: accessed-variable=VeAPSR_e_FaultSts_SnsrRefVolt5CktLo.Value
              OUT_VeAPSR_e_FaultSts_APP_Snsr1CktHi_Value: accessed-variable=VeAPSR_e_FaultSts_APP_Snsr1CktHi.Value
              OUT_VeAPSR_e_FaultSts_APP_Snsr1CktLo_Value: accessed-variable=VeAPSR_e_FaultSts_APP_Snsr1CktLo.Value
              OUT_VeAPSR_e_FaultSts_APP_Snsr2CktHi_Value: accessed-variable=VeAPSR_e_FaultSts_APP_Snsr2CktHi.Value
              OUT_VeAPSR_e_FaultSts_APP_Snsr2CktLo_Value: accessed-variable=VeAPSR_e_FaultSts_APP_Snsr2CktLo.Value
              OUT_VeAPSR_e_FaultSts_APP_Snsr12_Corr_Value: accessed-variable=VeAPSR_e_FaultSts_APP_Snsr12_Corr.Value
        APSR_PwrOn
          data-receive-point-by-arguments:
            13 x access:
              IN_AeAPSR_U_Pvs1MaxValue_Rx_AeAPSR_U_Pvs1MaxValue: accessed-variable=AeAPSR_U_Pvs1MaxValue_Rx.AeAPSR_U_Pvs1MaxValue
              IN_AeAPSR_U_Pvs1MinValue_Rx_AeAPSR_U_Pvs1MinValue: accessed-variable=AeAPSR_U_Pvs1MinValue_Rx.AeAPSR_U_Pvs1MinValue
              IN_AeAPSR_U_Pvs2MaxValue_Rx_AeAPSR_U_Pvs2MaxValue: accessed-variable=AeAPSR_U_Pvs2MaxValue_Rx.AeAPSR_U_Pvs2MaxValue
              IN_AeAPSR_U_Pvs2MinValue_Rx_AeAPSR_U_Pvs2MinValue: accessed-variable=AeAPSR_U_Pvs2MinValue_Rx.AeAPSR_U_Pvs2MinValue
              IN_AeAPSR_b_Pv1MaxTestFailed_Rx_AeAPSR_b_Pv1MaxTestFailed: accessed-variable=AeAPSR_b_Pv1MaxTestFailed_Rx.AeAPSR_b_Pv1MaxTestFailed
              IN_AeAPSR_b_Pv1MaxTestNotCmplt_Rx_AeAPSR_b_Pv1MaxTestNotCmplt: accessed-variable=AeAPSR_b_Pv1MaxTestNotCmplt_Rx.AeAPSR_b_Pv1MaxTestNotCmplt
              IN_AeAPSR_b_Pv1MinTestFailed_Rx_AeAPSR_b_Pv1MinTestFailed: accessed-variable=AeAPSR_b_Pv1MinTestFailed_Rx.AeAPSR_b_Pv1MinTestFailed
              IN_AeAPSR_b_Pv1MinTestNotCmplt_Rx_AeAPSR_b_Pv1MinTestNotCmplt: accessed-variable=AeAPSR_b_Pv1MinTestNotCmplt_Rx.AeAPSR_b_Pv1MinTestNotCmplt
              IN_AeAPSR_b_Pv2MaxTestFailed_Rx_AeAPSR_b_Pv2MaxTestFailed: accessed-variable=AeAPSR_b_Pv2MaxTestFailed_Rx.AeAPSR_b_Pv2MaxTestFailed
              IN_AeAPSR_b_Pv2MaxTestNotCmplt_Rx_AeAPSR_b_Pv2MaxTestNotCmplt: accessed-variable=AeAPSR_b_Pv2MaxTestNotCmplt_Rx.AeAPSR_b_Pv2MaxTestNotCmplt
              IN_AeAPSR_b_Pv2MinTestFailed_Rx_AeAPSR_b_Pv2MinTestFailed: accessed-variable=AeAPSR_b_Pv2MinTestFailed_Rx.AeAPSR_b_Pv2MinTestFailed
              IN_AeAPSR_b_Pv2MinTestNotCmplt_Rx_AeAPSR_b_Pv2MinTestNotCmplt: accessed-variable=AeAPSR_b_Pv2MinTestNotCmplt_Rx.AeAPSR_b_Pv2MinTestNotCmplt
              IN_NeAPSR_U_Lv1PvAdapt_Rx_NeAPSR_U_Lv1PvAdapt: accessed-variable=NeAPSR_U_Lv1PvAdapt_Rx.NeAPSR_U_Lv1PvAdapt
          data-send-points:
            55 x access:
              OUT_VeAPSR_b_RawPVS1_FA_Value: accessed-variable=VeAPSR_b_RawPVS1_FA.Value, variation-point={short-label=vpOUT_VeAPSR_b_RawPVS1_FA_Value, sw-syscond=1}
              OUT_VeAPSR_U_RawPVS1_Value: accessed-variable=VeAPSR_U_RawPVS1.Value, variation-point={short-label=vpOUT_VeAPSR_U_RawPVS1_Value, sw-syscond=1}
              OUT_VeAPSR_b_RawPVS2_FA_Value: accessed-variable=VeAPSR_b_RawPVS2_FA.Value, variation-point={short-label=vpOUT_VeAPSR_b_RawPVS2_FA_Value, sw-syscond=1}
              OUT_VeAPSR_U_RawPVS2_Value: accessed-variable=VeAPSR_U_RawPVS2.Value, variation-point={short-label=vpOUT_VeAPSR_U_RawPVS2_Value, sw-syscond=1}
              OUT_VeAPSR_Pct_AccelPedalEffPosition_Value: accessed-variable=VeAPSR_Pct_AccelPedalEffPosition.Value, variation-point={short-label=vpOUT_VeAPSR_Pct_AccelPedalEffPosition_Value, sw-syscond=1}
              OUT_VeAPSR_Pct_AccelPedalActPosition_Value: accessed-variable=VeAPSR_Pct_AccelPedalActPosition.Value, variation-point={short-label=vpOUT_VeAPSR_Pct_AccelPedalActPosition_Value, sw-syscond=1}
              OUT_VeAPSR_Pct_AccelPedalPstn_OBD_Value: accessed-variable=VeAPSR_Pct_AccelPedalPstn_OBD.Value
              OUT_VeAPSR_b_AccelPedalEffPositionFA_Value: accessed-variable=VeAPSR_b_AccelPedalEffPositionFA.Value
              OUT_VeAPSR_e_Lv1PVMode_Value: accessed-variable=VeAPSR_e_Lv1PVMode.Value
              OUT_VeAPSR_U_Lv1DelPVSHires_Value: accessed-variable=VeAPSR_U_Lv1DelPVSHires.Value
              OUT_VeAPSR_b_Lv1PvMod5HighCreepTrqReq_Value: accessed-variable=VeAPSR_b_Lv1PvMod5HighCreepTrqReq.Value
              OUT_VeAPSR_b_Lv1Pv1LimFailed_Value: accessed-variable=VeAPSR_b_Lv1Pv1LimFailed.Value
              OUT_VeAPSR_b_Lv1Pv2LimFailed_Value: accessed-variable=VeAPSR_b_Lv1Pv2LimFailed.Value
              OUT_VeAPSR_b_Lv1PvCohFailed_Value: accessed-variable=VeAPSR_b_Lv1PvCohFailed.Value
              OUT_VeAPSR_b_Lv1PvTrqLimitReq_Value: accessed-variable=VeAPSR_b_Lv1PvTrqLimitReq.Value
              OUT_VeAPSR_b_Lv1PvsValid_Value: accessed-variable=VeAPSR_b_Lv1PvsValid.Value
              OUT_VeAPSR_b_Lv1Pv1MinIPFailed_Value: accessed-variable=VeAPSR_b_Lv1Pv1MinIPFailed.Value
              OUT_VeAPSR_b_Lv1Pv1MaxIPFailed_Value: accessed-variable=VeAPSR_b_Lv1Pv1MaxIPFailed.Value
              OUT_VeAPSR_b_Lv1Pv2MinIPFailed_Value: accessed-variable=VeAPSR_b_Lv1Pv2MinIPFailed.Value
              OUT_VeAPSR_b_Lv1Pv2MaxIPFailed_Value: accessed-variable=VeAPSR_b_Lv1Pv2MaxIPFailed.Value
              OUT_VeAPSR_b_Failed5VRefOut_Value: accessed-variable=VeAPSR_b_Failed5VRefOut.Value
              OUT_VeAPSR_b_Failed5VRefAux_Value: accessed-variable=VeAPSR_b_Failed5VRefAux.Value
              OUT_VeAPSR_b_PVSMaxLearnt_Value: accessed-variable=VeAPSR_b_PVSMaxLearnt.Value
              OUT_VeAPSR_b_PVSMinLearnt_Value: accessed-variable=VeAPSR_b_PVSMinLearnt.Value
              OUT_VeAPSR_b_Lv1PvBrkActive_Value: accessed-variable=VeAPSR_b_Lv1PvBrkActive.Value
              OUT_VeAPSR_b_DrvBehAlert_Value: accessed-variable=VeAPSR_b_DrvBehAlert.Value
              OUT_VeAPSR_b_KickDown_Value: accessed-variable=VeAPSR_b_KickDown.Value
              OUT_VeAPSR_e_FaultSts_APP_Snsr1_MaxStpPerf_Value: accessed-variable=VeAPSR_e_FaultSts_APP_Snsr1_MaxStpPerf.Value
              OUT_VeAPSR_e_FaultSts_APP_Snsr1_MinStpPerf_Value: accessed-variable=VeAPSR_e_FaultSts_APP_Snsr1_MinStpPerf.Value
              OUT_VeAPSR_e_FaultSts_APP_Snsr2_MaxStpPerf_Value: accessed-variable=VeAPSR_e_FaultSts_APP_Snsr2_MaxStpPerf.Value
              OUT_VeAPSR_e_FaultSts_APP_Snsr2_MinStpPerf_Value: accessed-variable=VeAPSR_e_FaultSts_APP_Snsr2_MinStpPerf.Value
              OUT_VeAPSR_e_FaultSts_BrkAccStuckPdl_Value: accessed-variable=VeAPSR_e_FaultSts_BrkAccStuckPdl.Value
              OUT_VeAPSR_e_FaultSts_SnsrRefVolt2Noisy_Value: accessed-variable=VeAPSR_e_FaultSts_SnsrRefVolt2Noisy.Value
              OUT_VeAPSR_e_FaultSts_SnsrRefVolt6CktHi_Value: accessed-variable=VeAPSR_e_FaultSts_SnsrRefVolt6CktHi.Value
              OUT_VeAPSR_e_FaultSts_SnsrRefVolt6CktLo_Value: accessed-variable=VeAPSR_e_FaultSts_SnsrRefVolt6CktLo.Value
              OUT_VeAPSR_e_FaultSts_SnsrRefVolt1Noisy_Value: accessed-variable=VeAPSR_e_FaultSts_SnsrRefVolt1Noisy.Value
              OUT_VeAPSR_e_FaultSts_SnsrRefVolt5CktHi_Value: accessed-variable=VeAPSR_e_FaultSts_SnsrRefVolt5CktHi.Value
              OUT_VeAPSR_e_FaultSts_SnsrRefVolt5CktLo_Value: accessed-variable=VeAPSR_e_FaultSts_SnsrRefVolt5CktLo.Value
              OUT_VeAPSR_e_FaultSts_APP_Snsr1CktHi_Value: accessed-variable=VeAPSR_e_FaultSts_APP_Snsr1CktHi.Value
              OUT_VeAPSR_e_FaultSts_APP_Snsr1CktLo_Value: accessed-variable=VeAPSR_e_FaultSts_APP_Snsr1CktLo.Value
              OUT_VeAPSR_e_FaultSts_APP_Snsr2CktHi_Value: accessed-variable=VeAPSR_e_FaultSts_APP_Snsr2CktHi.Value
              OUT_VeAPSR_e_FaultSts_APP_Snsr2CktLo_Value: accessed-variable=VeAPSR_e_FaultSts_APP_Snsr2CktLo.Value
              OUT_VeAPSR_e_FaultSts_APP_Snsr12_Corr_Value: accessed-variable=VeAPSR_e_FaultSts_APP_Snsr12_Corr.Value
              OUT_VeAPSR_U_Pvs1MaxValue_Value: accessed-variable=VeAPSR_U_Pvs1MaxValue.Value
              OUT_VeAPSR_U_Pvs1MinValue_Value: accessed-variable=VeAPSR_U_Pvs1MinValue.Value
              OUT_VeAPSR_U_Pvs2MaxValue_Value: accessed-variable=VeAPSR_U_Pvs2MaxValue.Value
              OUT_VeAPSR_U_Pvs2MinValue_Value: accessed-variable=VeAPSR_U_Pvs2MinValue.Value
              OUT_VeAPSR_b_Pv1MaxTestFailed_Value: accessed-variable=VeAPSR_b_Pv1MaxTestFailed.Value
              OUT_VeAPSR_b_Pv1MaxTestNotCmplt_Value: accessed-variable=VeAPSR_b_Pv1MaxTestNotCmplt.Value
              OUT_VeAPSR_b_Pv1MinTestFailed_Value: accessed-variable=VeAPSR_b_Pv1MinTestFailed.Value
              OUT_VeAPSR_b_Pv1MinTestNotCmplt_Value: accessed-variable=VeAPSR_b_Pv1MinTestNotCmplt.Value
              OUT_VeAPSR_b_Pv2MaxTestFailed_Value: accessed-variable=VeAPSR_b_Pv2MaxTestFailed.Value
              OUT_VeAPSR_b_Pv2MaxTestNotCmplt_Value: accessed-variable=VeAPSR_b_Pv2MaxTestNotCmplt.Value
              OUT_VeAPSR_b_Pv2MinTestFailed_Value: accessed-variable=VeAPSR_b_Pv2MinTestFailed.Value
              OUT_VeAPSR_b_Pv2MinTestNotCmplt_Value: accessed-variable=VeAPSR_b_Pv2MinTestNotCmplt.Value
          written-local-variables:
            8 x access:
              WV_LeAPSR_b_AccelPedalEffPositionFA_write_IRV: accessed-variable=LeAPSR_b_AccelPedalEffPositionFA_write_IRV
              WV_RawAux5V_FA_Init_write_IRV: accessed-variable=RawAux5V_FA_Init_write_IRV, variation-point={short-label=vpWV_RawAux5V_FA_Init_write_IRV, sw-syscond=1}
              WV_RawAux5V_Init_write_IRV: accessed-variable=RawAux5V_Init_write_IRV, variation-point={short-label=vpWV_RawAux5V_Init_write_IRV, sw-syscond=1}
              WV_RawOut5V_FA_Init_write_IRV: accessed-variable=RawOut5V_FA_Init_write_IRV, variation-point={short-label=vpWV_RawOut5V_FA_Init_write_IRV, sw-syscond=1}
              WV_RawOut5V_Init_write_IRV: accessed-variable=RawOut5V_Init_write_IRV, variation-point={short-label=vpWV_RawOut5V_Init_write_IRV, sw-syscond=1}
              WV_RawPVS1_write_IRV: accessed-variable=RawPVS1_write_IRV, variation-point={short-label=vpWV_RawPVS1_write_IRV, sw-syscond=1}
              WV_RawPVS2_write_IRV: accessed-variable=RawPVS2_write_IRV, variation-point={short-label=vpWV_RawPVS2_write_IRV, sw-syscond=1}
              WV_ServRoutStrt_write_IRV: accessed-variable=ServRoutStrt_write_IRV, variation-point={short-label=vpWV_ServRoutStrt_write_IRV, sw-syscond=1}
        APSR_FastTEF: variation-point={short-label=vpAPSR_FastTEF, sw-syscond=1}
          data-receive-point-by-arguments:
            31 x access:
              IN_VeBRKR_b_BrkPedalDscrtInptFA_Value: accessed-variable=VeBRKR_b_BrkPedalDscrtInptFA.Value, variation-point={short-label=vpIN_VeBRKR_b_BrkPedalDscrtInptFA_Value, sw-syscond=1}
              IN_VeBRKR_e_BrakeSrc_Value: accessed-variable=VeBRKR_e_BrakeSrc.Value, variation-point={short-label=vpIN_VeBRKR_e_BrakeSrc_Value, sw-syscond=1}
              IN_VeBRKR_e_BrkPedalDscrtInpt_Value: accessed-variable=VeBRKR_e_BrkPedalDscrtInpt.Value, variation-point={short-label=vpIN_VeBRKR_e_BrkPedalDscrtInpt_Value, sw-syscond=1}
              IN_VeBSWR_e_PedalSensorEEProgStatus_Value: accessed-variable=VeBSWR_e_PedalSensorEEProgStatus.Value, variation-point={short-label=vpIN_VeBSWR_e_PedalSensorEEProgStatus_Value, sw-syscond=1}
              IN_VeCSVR_e_VehSpdSrc_Value: accessed-variable=VeCSVR_e_VehSpdSrc.Value, variation-point={short-label=vpIN_VeCSVR_e_VehSpdSrc_Value, sw-syscond=1}
              IN_VeCSVR_v_VehSpd_Value: accessed-variable=VeCSVR_v_VehSpd.Value, variation-point={short-label=vpIN_VeCSVR_v_VehSpd_Value, sw-syscond=1}
              IN_VeDFIR_b_DsblDiagFailSafe_Value: accessed-variable=VeDFIR_b_DsblDiagFailSafe.Value, variation-point={short-label=vpIN_VeDFIR_b_DsblDiagFailSafe_Value, sw-syscond=1}
              IN_VeDFIR_b_IsDiagGlobalConditionsValid_Value: accessed-variable=VeDFIR_b_IsDiagGlobalConditionsValid.Value, variation-point={short-label=vpIN_VeDFIR_b_IsDiagGlobalConditionsValid_Value, sw-syscond=1}
              IN_VeDFIR_b_PostCodeClrDiagDsbl_Value: accessed-variable=VeDFIR_b_PostCodeClrDiagDsbl.Value, variation-point={short-label=vpIN_VeDFIR_b_PostCodeClrDiagDsbl_Value, sw-syscond=1}
              IN_VeDMAB_y_StatusByte_APP_Snsr12_Corr_Value: accessed-variable=VeDMAB_y_StatusByte_APP_Snsr12_Corr.Value, variation-point={short-label=vpIN_VeDMAB_y_StatusByte_APP_Snsr12_Corr_Value, sw-syscond=1}
              IN_VeDMAB_y_StatusByte_APP_Snsr1CktHi_Value: accessed-variable=VeDMAB_y_StatusByte_APP_Snsr1CktHi.Value, variation-point={short-label=vpIN_VeDMAB_y_StatusByte_APP_Snsr1CktHi_Value, sw-syscond=1}
              IN_VeDMAB_y_StatusByte_APP_Snsr1CktLo_Value: accessed-variable=VeDMAB_y_StatusByte_APP_Snsr1CktLo.Value, variation-point={short-label=vpIN_VeDMAB_y_StatusByte_APP_Snsr1CktLo_Value, sw-syscond=1}
              IN_VeDMAB_y_StatusByte_APP_Snsr1_MaxStpPerf_Value: accessed-variable=VeDMAB_y_StatusByte_APP_Snsr1_MaxStpPerf.Value, variation-point={short-label=vpIN_VeDMAB_y_StatusByte_APP_Snsr1_MaxStpPerf_Value, sw-syscond=1}
              IN_VeDMAB_y_StatusByte_APP_Snsr1_MinStpPerf_Value: accessed-variable=VeDMAB_y_StatusByte_APP_Snsr1_MinStpPerf.Value, variation-point={short-label=vpIN_VeDMAB_y_StatusByte_APP_Snsr1_MinStpPerf_Value, sw-syscond=1}
              IN_VeDMAB_y_StatusByte_APP_Snsr2CktHi_Value: accessed-variable=VeDMAB_y_StatusByte_APP_Snsr2CktHi.Value, variation-point={short-label=vpIN_VeDMAB_y_StatusByte_APP_Snsr2CktHi_Value, sw-syscond=1}
              IN_VeDMAB_y_StatusByte_APP_Snsr2CktLo_Value: accessed-variable=VeDMAB_y_StatusByte_APP_Snsr2CktLo.Value, variation-point={short-label=vpIN_VeDMAB_y_StatusByte_APP_Snsr2CktLo_Value, sw-syscond=1}
              IN_VeDMAB_y_StatusByte_APP_Snsr2_MaxStpPerf_Value: accessed-variable=VeDMAB_y_StatusByte_APP_Snsr2_MaxStpPerf.Value, variation-point={short-label=vpIN_VeDMAB_y_StatusByte_APP_Snsr2_MaxStpPerf_Value, sw-syscond=1}
              IN_VeDMAB_y_StatusByte_APP_Snsr2_MinStpPerf_Value: accessed-variable=VeDMAB_y_StatusByte_APP_Snsr2_MinStpPerf.Value, variation-point={short-label=vpIN_VeDMAB_y_StatusByte_APP_Snsr2_MinStpPerf_Value, sw-syscond=1}
              IN_VeDMAB_y_StatusByte_BrkAccStuckPdl_Value: accessed-variable=VeDMAB_y_StatusByte_BrkAccStuckPdl.Value, variation-point={short-label=vpIN_VeDMAB_y_StatusByte_BrkAccStuckPdl_Value, sw-syscond=1}
              IN_VeDMAB_y_StatusByte_SnsrRefVolt1Noisy_Value: accessed-variable=VeDMAB_y_StatusByte_SnsrRefVolt1Noisy.Value, variation-point={short-label=vpIN_VeDMAB_y_StatusByte_SnsrRefVolt1Noisy_Value, sw-syscond=1}
              IN_VeDMAB_y_StatusByte_SnsrRefVolt2Noisy_Value: accessed-variable=VeDMAB_y_StatusByte_SnsrRefVolt2Noisy.Value, variation-point={short-label=vpIN_VeDMAB_y_StatusByte_SnsrRefVolt2Noisy_Value, sw-syscond=1}
              IN_VeDMAB_y_StatusByte_SnsrRefVolt5CktHi_Value: accessed-variable=VeDMAB_y_StatusByte_SnsrRefVolt5CktHi.Value, variation-point={short-label=vpIN_VeDMAB_y_StatusByte_SnsrRefVolt5CktHi_Value, sw-syscond=1}
              IN_VeDMAB_y_StatusByte_SnsrRefVolt5CktLo_Value: accessed-variable=VeDMAB_y_StatusByte_SnsrRefVolt5CktLo.Value, variation-point={short-label=vpIN_VeDMAB_y_StatusByte_SnsrRefVolt5CktLo_Value, sw-syscond=1}
              IN_VeDMAB_y_StatusByte_SnsrRefVolt6CktHi_Value: accessed-variable=VeDMAB_y_StatusByte_SnsrRefVolt6CktHi.Value, variation-point={short-label=vpIN_VeDMAB_y_StatusByte_SnsrRefVolt6CktHi_Value, sw-syscond=1}
              IN_VeDMAB_y_StatusByte_SnsrRefVolt6CktLo_Value: accessed-variable=VeDMAB_y_StatusByte_SnsrRefVolt6CktLo.Value, variation-point={short-label=vpIN_VeDMAB_y_StatusByte_SnsrRefVolt6CktLo_Value, sw-syscond=1}
              IN_VeHMIR_b_DriveReady_Value: accessed-variable=VeHMIR_b_DriveReady.Value, variation-point={short-label=vpIN_VeHMIR_b_DriveReady_Value, sw-syscond=1}
              IN_VeHPMR_b_PropSysActv_Value: accessed-variable=VeHPMR_b_PropSysActv.Value, variation-point={short-label=vpIN_VeHPMR_b_PropSysActv_Value, sw-syscond=1}
              IN_VePLTR_b_InFieldMode_Value: accessed-variable=VePLTR_b_InFieldMode.Value, variation-point={short-label=vpIN_VePLTR_b_InFieldMode_Value, sw-syscond=1}
              IN_VePMDR_e_PMM_PowerMode_Value: accessed-variable=VePMDR_e_PMM_PowerMode.Value, variation-point={short-label=vpIN_VePMDR_e_PMM_PowerMode_Value, sw-syscond=1}
              IN_VePSMR_Pct_Lv2AccelPedalEffPosition_Value: accessed-variable=VePSMR_Pct_Lv2AccelPedalEffPosition.Value, variation-point={short-label=vpIN_VePSMR_Pct_Lv2AccelPedalEffPosition_Value, sw-syscond=1}
              IN_VeTRGR_e_VldtdTransRngSt_Value: accessed-variable=VeTRGR_e_VldtdTransRngSt.Value, variation-point={short-label=vpIN_VeTRGR_e_VldtdTransRngSt_Value, sw-syscond=1}
          data-send-points:
            62 x access:
              OUT_VeAPSR_e_Lv1PVMode_Value: accessed-variable=VeAPSR_e_Lv1PVMode.Value
              OUT_VeAPSR_Pct_AccelPedalEffPosition_Value: accessed-variable=VeAPSR_Pct_AccelPedalEffPosition.Value, variation-point={short-label=vpOUT_VeAPSR_Pct_AccelPedalEffPosition_Value, sw-syscond=1}
              OUT_VeAPSR_Pct_AccelPedalActPosition_Value: accessed-variable=VeAPSR_Pct_AccelPedalActPosition.Value, variation-point={short-label=vpOUT_VeAPSR_Pct_AccelPedalActPosition_Value, sw-syscond=1}
              OUT_VeAPSR_U_Lv1DelPVSHires_Value: accessed-variable=VeAPSR_U_Lv1DelPVSHires.Value
              OUT_VeAPSR_b_Lv1PvMod5HighCreepTrqReq_Value: accessed-variable=VeAPSR_b_Lv1PvMod5HighCreepTrqReq.Value
              OUT_VeAPSR_b_Lv1Pv1LimFailed_Value: accessed-variable=VeAPSR_b_Lv1Pv1LimFailed.Value
              OUT_VeAPSR_b_Lv1Pv2LimFailed_Value: accessed-variable=VeAPSR_b_Lv1Pv2LimFailed.Value
              OUT_VeAPSR_b_Lv1PvCohFailed_Value: accessed-variable=VeAPSR_b_Lv1PvCohFailed.Value
              OUT_VeAPSR_b_Lv1PvTrqLimitReq_Value: accessed-variable=VeAPSR_b_Lv1PvTrqLimitReq.Value
              OUT_VeAPSR_b_Lv1PvsValid_Value: accessed-variable=VeAPSR_b_Lv1PvsValid.Value
              OUT_VeAPSR_b_Lv1Pv1MinIPFailed_Value: accessed-variable=VeAPSR_b_Lv1Pv1MinIPFailed.Value
              OUT_VeAPSR_b_Lv1Pv1MaxIPFailed_Value: accessed-variable=VeAPSR_b_Lv1Pv1MaxIPFailed.Value
              OUT_VeAPSR_b_Lv1Pv2MinIPFailed_Value: accessed-variable=VeAPSR_b_Lv1Pv2MinIPFailed.Value
              OUT_VeAPSR_b_Lv1Pv2MaxIPFailed_Value: accessed-variable=VeAPSR_b_Lv1Pv2MaxIPFailed.Value
              OUT_VeAPSR_b_Failed5VRefOut_Value: accessed-variable=VeAPSR_b_Failed5VRefOut.Value
              OUT_VeAPSR_b_Failed5VRefAux_Value: accessed-variable=VeAPSR_b_Failed5VRefAux.Value
              OUT_VeAPSR_b_PVSMaxLearnt_Value: accessed-variable=VeAPSR_b_PVSMaxLearnt.Value
              OUT_VeAPSR_b_PVSMinLearnt_Value: accessed-variable=VeAPSR_b_PVSMinLearnt.Value
              OUT_VeAPSR_b_Lv1PvBrkActive_Value: accessed-variable=VeAPSR_b_Lv1PvBrkActive.Value
              OUT_VeAPSR_b_DrvBehAlert_Value: accessed-variable=VeAPSR_b_DrvBehAlert.Value
              OUT_VeAPSR_b_AccelPedalEffPositionFA_Value: accessed-variable=VeAPSR_b_AccelPedalEffPositionFA.Value
              OUT_VeAPSR_b_KickDown_Value: accessed-variable=VeAPSR_b_KickDown.Value
              OUT_VeAPSR_e_FaultSts_APP_Snsr1_MaxStpPerf_Value: accessed-variable=VeAPSR_e_FaultSts_APP_Snsr1_MaxStpPerf.Value
              OUT_VeAPSR_e_FaultSts_APP_Snsr1_MinStpPerf_Value: accessed-variable=VeAPSR_e_FaultSts_APP_Snsr1_MinStpPerf.Value
              OUT_VeAPSR_e_FaultSts_APP_Snsr2_MaxStpPerf_Value: accessed-variable=VeAPSR_e_FaultSts_APP_Snsr2_MaxStpPerf.Value
              OUT_VeAPSR_e_FaultSts_APP_Snsr2_MinStpPerf_Value: accessed-variable=VeAPSR_e_FaultSts_APP_Snsr2_MinStpPerf.Value
              OUT_VeAPSR_e_FaultSts_BrkAccStuckPdl_Value: accessed-variable=VeAPSR_e_FaultSts_BrkAccStuckPdl.Value
              OUT_VeAPSR_e_FaultSts_SnsrRefVolt2Noisy_Value: accessed-variable=VeAPSR_e_FaultSts_SnsrRefVolt2Noisy.Value
              OUT_VeAPSR_e_FaultSts_SnsrRefVolt6CktHi_Value: accessed-variable=VeAPSR_e_FaultSts_SnsrRefVolt6CktHi.Value
              OUT_VeAPSR_e_FaultSts_SnsrRefVolt6CktLo_Value: accessed-variable=VeAPSR_e_FaultSts_SnsrRefVolt6CktLo.Value
              OUT_VeAPSR_e_FaultSts_SnsrRefVolt1Noisy_Value: accessed-variable=VeAPSR_e_FaultSts_SnsrRefVolt1Noisy.Value
              OUT_VeAPSR_e_FaultSts_SnsrRefVolt5CktHi_Value: accessed-variable=VeAPSR_e_FaultSts_SnsrRefVolt5CktHi.Value
              OUT_VeAPSR_e_FaultSts_SnsrRefVolt5CktLo_Value: accessed-variable=VeAPSR_e_FaultSts_SnsrRefVolt5CktLo.Value
              OUT_VeAPSR_e_FaultSts_APP_Snsr1CktHi_Value: accessed-variable=VeAPSR_e_FaultSts_APP_Snsr1CktHi.Value
              OUT_VeAPSR_e_FaultSts_APP_Snsr1CktLo_Value: accessed-variable=VeAPSR_e_FaultSts_APP_Snsr1CktLo.Value
              OUT_VeAPSR_e_FaultSts_APP_Snsr2CktHi_Value: accessed-variable=VeAPSR_e_FaultSts_APP_Snsr2CktHi.Value
              OUT_VeAPSR_e_FaultSts_APP_Snsr2CktLo_Value: accessed-variable=VeAPSR_e_FaultSts_APP_Snsr2CktLo.Value
              OUT_VeAPSR_e_FaultSts_APP_Snsr12_Corr_Value: accessed-variable=VeAPSR_e_FaultSts_APP_Snsr12_Corr.Value
              OUT_AeAPSR_b_Pv1MaxTestFailed_AeAPSR_b_Pv1MaxTestFailed: accessed-variable=AeAPSR_b_Pv1MaxTestFailed.AeAPSR_b_Pv1MaxTestFailed, variation-point={short-label=vpOUT_AeAPSR_b_Pv1MaxTestFailed_AeAPSR_b_Pv1MaxTestFailed, sw-syscond=1}
              OUT_AeAPSR_b_Pv1MaxTestNotCmplt_AeAPSR_b_Pv1MaxTestNotCmplt: accessed-variable=AeAPSR_b_Pv1MaxTestNotCmplt.AeAPSR_b_Pv1MaxTestNotCmplt, variation-point={short-label=vpOUT_AeAPSR_b_Pv1MaxTestNotCmplt_AeAPSR_b_Pv1MaxTestNotCmplt, sw-syscond=1}
              OUT_AeAPSR_b_Pv1MinTestFailed_AeAPSR_b_Pv1MinTestFailed: accessed-variable=AeAPSR_b_Pv1MinTestFailed.AeAPSR_b_Pv1MinTestFailed, variation-point={short-label=vpOUT_AeAPSR_b_Pv1MinTestFailed_AeAPSR_b_Pv1MinTestFailed, sw-syscond=1}
              OUT_AeAPSR_b_Pv1MinTestNotCmplt_AeAPSR_b_Pv1MinTestNotCmplt: accessed-variable=AeAPSR_b_Pv1MinTestNotCmplt.AeAPSR_b_Pv1MinTestNotCmplt, variation-point={short-label=vpOUT_AeAPSR_b_Pv1MinTestNotCmplt_AeAPSR_b_Pv1MinTestNotCmplt, sw-syscond=1}
              OUT_AeAPSR_b_Pv2MaxTestFailed_AeAPSR_b_Pv2MaxTestFailed: accessed-variable=AeAPSR_b_Pv2MaxTestFailed.AeAPSR_b_Pv2MaxTestFailed, variation-point={short-label=vpOUT_AeAPSR_b_Pv2MaxTestFailed_AeAPSR_b_Pv2MaxTestFailed, sw-syscond=1}
              OUT_AeAPSR_b_Pv2MaxTestNotCmplt_AeAPSR_b_Pv2MaxTestNotCmplt: accessed-variable=AeAPSR_b_Pv2MaxTestNotCmplt.AeAPSR_b_Pv2MaxTestNotCmplt, variation-point={short-label=vpOUT_AeAPSR_b_Pv2MaxTestNotCmplt_AeAPSR_b_Pv2MaxTestNotCmplt, sw-syscond=1}
              OUT_AeAPSR_b_Pv2MinTestFailed_AeAPSR_b_Pv2MinTestFailed: accessed-variable=AeAPSR_b_Pv2MinTestFailed.AeAPSR_b_Pv2MinTestFailed, variation-point={short-label=vpOUT_AeAPSR_b_Pv2MinTestFailed_AeAPSR_b_Pv2MinTestFailed, sw-syscond=1}
              OUT_AeAPSR_b_Pv2MinTestNotCmplt_AeAPSR_b_Pv2MinTestNotCmplt: accessed-variable=AeAPSR_b_Pv2MinTestNotCmplt.AeAPSR_b_Pv2MinTestNotCmplt, variation-point={short-label=vpOUT_AeAPSR_b_Pv2MinTestNotCmplt_AeAPSR_b_Pv2MinTestNotCmplt, sw-syscond=1}
              OUT_AeAPSR_U_Pvs1MaxValue_AeAPSR_U_Pvs1MaxValue: accessed-variable=AeAPSR_U_Pvs1MaxValue.AeAPSR_U_Pvs1MaxValue, variation-point={short-label=vpOUT_AeAPSR_U_Pvs1MaxValue_AeAPSR_U_Pvs1MaxValue, sw-syscond=1}
              OUT_AeAPSR_U_Pvs1MinValue_AeAPSR_U_Pvs1MinValue: accessed-variable=AeAPSR_U_Pvs1MinValue.AeAPSR_U_Pvs1MinValue, variation-point={short-label=vpOUT_AeAPSR_U_Pvs1MinValue_AeAPSR_U_Pvs1MinValue, sw-syscond=1}
              OUT_AeAPSR_U_Pvs2MaxValue_AeAPSR_U_Pvs2MaxValue: accessed-variable=AeAPSR_U_Pvs2MaxValue.AeAPSR_U_Pvs2MaxValue, variation-point={short-label=vpOUT_AeAPSR_U_Pvs2MaxValue_AeAPSR_U_Pvs2MaxValue, sw-syscond=1}
              OUT_AeAPSR_U_Pvs2MinValue_AeAPSR_U_Pvs2MinValue: accessed-variable=AeAPSR_U_Pvs2MinValue.AeAPSR_U_Pvs2MinValue, variation-point={short-label=vpOUT_AeAPSR_U_Pvs2MinValue_AeAPSR_U_Pvs2MinValue, sw-syscond=1}
              OUT_VeAPSR_U_Pvs1MaxValue_Value: accessed-variable=VeAPSR_U_Pvs1MaxValue.Value
              OUT_VeAPSR_U_Pvs1MinValue_Value: accessed-variable=VeAPSR_U_Pvs1MinValue.Value
              OUT_VeAPSR_U_Pvs2MaxValue_Value: accessed-variable=VeAPSR_U_Pvs2MaxValue.Value
              OUT_VeAPSR_U_Pvs2MinValue_Value: accessed-variable=VeAPSR_U_Pvs2MinValue.Value
              OUT_VeAPSR_b_Pv1MaxTestFailed_Value: accessed-variable=VeAPSR_b_Pv1MaxTestFailed.Value
              OUT_VeAPSR_b_Pv1MaxTestNotCmplt_Value: accessed-variable=VeAPSR_b_Pv1MaxTestNotCmplt.Value
              OUT_VeAPSR_b_Pv1MinTestFailed_Value: accessed-variable=VeAPSR_b_Pv1MinTestFailed.Value
              OUT_VeAPSR_b_Pv1MinTestNotCmplt_Value: accessed-variable=VeAPSR_b_Pv1MinTestNotCmplt.Value
              OUT_VeAPSR_b_Pv2MaxTestFailed_Value: accessed-variable=VeAPSR_b_Pv2MaxTestFailed.Value
              OUT_VeAPSR_b_Pv2MaxTestNotCmplt_Value: accessed-variable=VeAPSR_b_Pv2MaxTestNotCmplt.Value
              OUT_VeAPSR_b_Pv2MinTestFailed_Value: accessed-variable=VeAPSR_b_Pv2MinTestFailed.Value
              OUT_VeAPSR_b_Pv2MinTestNotCmplt_Value: accessed-variable=VeAPSR_b_Pv2MinTestNotCmplt.Value
          read-local-variables:
            5 x access:
              RV_RawAux5V_Init_write_IRV: accessed-variable=RawAux5V_Init_write_IRV, variation-point={short-label=vpRV_RawAux5V_Init_write_IRV, sw-syscond=1}
              RV_RawOut5V_Init_write_IRV: accessed-variable=RawOut5V_Init_write_IRV, variation-point={short-label=vpRV_RawOut5V_Init_write_IRV, sw-syscond=1}
              RV_RawPVS1_write_IRV: accessed-variable=RawPVS1_write_IRV, variation-point={short-label=vpRV_RawPVS1_write_IRV, sw-syscond=1}
              RV_RawPVS2_write_IRV: accessed-variable=RawPVS2_write_IRV, variation-point={short-label=vpRV_RawPVS2_write_IRV, sw-syscond=1}
              RV_ServRoutStrt_write_IRV: accessed-variable=ServRoutStrt_write_IRV, variation-point={short-label=vpRV_ServRoutStrt_write_IRV, sw-syscond=1}
        APSR_PwrOff
          data-send-points:
            access OUT_NeAPSR_U_Lv1PvAdapt_NeAPSR_U_Lv1PvAdapt: accessed-variable=NeAPSR_U_Lv1PvAdapt.NeAPSR_U_Lv1PvAdapt
        Routine_RC130C_AccPedLea: variation-point={short-label=vpRoutine_RC130C_AccPedLea, sw-syscond=1}
          data-receive-point-by-arguments:
            access IN_VeDCAB_e_Routine_RC130C_AccPedLea_Op_Value: accessed-variable=VeDCAB_e_Routine_RC130C_AccPedLea_Op.Value, variation-point={short-label=vpIN_VeDCAB_e_Routine_RC130C_AccPedLea_Op_Value, sw-syscond=1}
          written-local-variables:
            access WV_ServRoutStrt_write_IRV: accessed-variable=ServRoutStrt_write_IRV, variation-point={short-label=vpWV_ServRoutStrt_write_IRV, sw-syscond=1}
        DIDWrite_RWD9E21_IPEEETCPVS1MAXVAL
          data-receive-point-by-arguments:
            access IN_VeDCAB_U_Pvs1MaxValue_DidWrite_Value: accessed-variable=VeDCAB_U_Pvs1MaxValue_DidWrite.Value
        DIDWrite_RWD9E23_IPEEETCPVS2MAXVAL
          data-receive-point-by-arguments:
            access IN_VeDCAB_U_Pvs2MaxValue_DidWrite_Value: accessed-variable=VeDCAB_U_Pvs2MaxValue_DidWrite.Value
        DIDWrite_RWD9E22_IPEEETCPVS2MINVAL
          data-receive-point-by-arguments:
            access IN_VeDCAB_U_Pvs2MinValue_DidWrite_Value: accessed-variable=VeDCAB_U_Pvs2MinValue_DidWrite.Value
        DIDWrite_RWD9E20_IPEEETCPVS1MINVAL
          data-receive-point-by-arguments:
            access IN_VeDCAB_U_Pvs1MinValue_DidWrite_Value: accessed-variable=VeDCAB_U_Pvs1MinValue_DidWrite.Value
        DIDWrite_RWD9E15_IPEEREG16FLG
          data-receive-point-by-arguments:
            8 x access:
              IN_VeDCAB_b_Pv1MaxTestFailed_DidWrite_Value: accessed-variable=VeDCAB_b_Pv1MaxTestFailed_DidWrite.Value
              IN_VeDCAB_b_Pv1MaxTestNotCmplt_DidWrite_Value: accessed-variable=VeDCAB_b_Pv1MaxTestNotCmplt_DidWrite.Value
              IN_VeDCAB_b_Pv1MinTestFailed_DidWrite_Value: accessed-variable=VeDCAB_b_Pv1MinTestFailed_DidWrite.Value
              IN_VeDCAB_b_Pv1MinTestNotCmplt_DidWrite_Value: accessed-variable=VeDCAB_b_Pv1MinTestNotCmplt_DidWrite.Value
              IN_VeDCAB_b_Pv2MaxTestFailed_DidWrite_Value: accessed-variable=VeDCAB_b_Pv2MaxTestFailed_DidWrite.Value
              IN_VeDCAB_b_Pv2MaxTestNotCmplt_DidWrite_Value: accessed-variable=VeDCAB_b_Pv2MaxTestNotCmplt_DidWrite.Value
              IN_VeDCAB_b_Pv2MinTestFailed_DidWrite_Value: accessed-variable=VeDCAB_b_Pv2MinTestFailed_DidWrite.Value
              IN_VeDCAB_b_Pv2MinTestNotCmplt_DidWrite_Value: accessed-variable=VeDCAB_b_Pv2MinTestNotCmplt_DidWrite.Value
        PokeAPSR_U_RawAux5V: variation-point={short-label=vpPokeAPSR_U_RawAux5V, sw-syscond=1}
          written-local-variables:
            access WV_RawAux5V_Init_write_IRV: accessed-variable=RawAux5V_Init_write_IRV, variation-point={short-label=vpWV_RawAux5V_Init_write_IRV, sw-syscond=1}
            access WV_RawAux5V_FA_Init_write_IRV: accessed-variable=RawAux5V_FA_Init_write_IRV, variation-point={short-label=vpWV_RawAux5V_FA_Init_write_IRV, sw-syscond=1}
        PokeAPSR_U_RawOut5V: variation-point={short-label=vpPokeAPSR_U_RawOut5V, sw-syscond=1}
          written-local-variables:
            access WV_RawOut5V_Init_write_IRV: accessed-variable=RawOut5V_Init_write_IRV, variation-point={short-label=vpWV_RawOut5V_Init_write_IRV, sw-syscond=1}
            access WV_RawOut5V_FA_Init_write_IRV: accessed-variable=RawOut5V_FA_Init_write_IRV, variation-point={short-label=vpWV_RawOut5V_FA_Init_write_IRV, sw-syscond=1}
        PokeAPSR_U_RawPVS1: variation-point={short-label=vpPokeAPSR_U_RawPVS1, sw-syscond=1}
          data-send-points:
            access OUT_VeAPSR_U_RawPVS1_Value: accessed-variable=VeAPSR_U_RawPVS1.Value, variation-point={short-label=vpOUT_VeAPSR_U_RawPVS1_Value, sw-syscond=1}
            access OUT_VeAPSR_b_RawPVS1_FA_Value: accessed-variable=VeAPSR_b_RawPVS1_FA.Value, variation-point={short-label=vpOUT_VeAPSR_b_RawPVS1_FA_Value, sw-syscond=1}
          written-local-variables:
            access WV_RawPVS1_write_IRV: accessed-variable=RawPVS1_write_IRV, variation-point={short-label=vpWV_RawPVS1_write_IRV, sw-syscond=1}
        PokeAPSR_U_RawPVS2: variation-point={short-label=vpPokeAPSR_U_RawPVS2, sw-syscond=1}
          data-send-points:
            access OUT_VeAPSR_U_RawPVS2_Value: accessed-variable=VeAPSR_U_RawPVS2.Value, variation-point={short-label=vpOUT_VeAPSR_U_RawPVS2_Value, sw-syscond=1}
            access OUT_VeAPSR_b_RawPVS2_FA_Value: accessed-variable=VeAPSR_b_RawPVS2_FA.Value, variation-point={short-label=vpOUT_VeAPSR_b_RawPVS2_FA_Value, sw-syscond=1}
          written-local-variables:
            access WV_RawPVS2_write_IRV: accessed-variable=RawPVS2_write_IRV, variation-point={short-label=vpWV_RawPVS2_write_IRV, sw-syscond=1}
      6 x variation point proxy, all with category=CONDITION:
        Variant_APSR_1: condition-access=0
        Variant_APSR_3: condition-access=0
        Variant_APSR_4: condition-access=1
        Variant_APSR_5: condition-access=0
        Variant_APSR_6: condition-access=0
        Variant_APSR_7: condition-access=1
